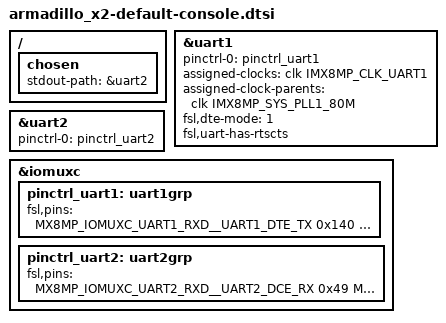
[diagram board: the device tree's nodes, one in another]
/*
 * Copyright (C) 2021 Atmark Techno, Inc. All Rights Reserved.
 *
 * SPDX-License-Identifier: (GPL-2.0 OR MIT)
 */

/ {
	chosen {
		stdout-path = &uart2;
	};
};

&uart1 {
	// M2 slot (bluetooth)
	pinctrl-names = "default";
	pinctrl-0 = <&pinctrl_uart1>;
	assigned-clocks = <&clk IMX8MP_CLK_UART1>;
	assigned-clock-parents = <&clk IMX8MP_SYS_PLL1_80M>;
	status = "okay";
	fsl,dte-mode = <1>;
	fsl,uart-has-rtscts;
};

&uart2 {
	pinctrl-names = "default";
	pinctrl-0 = <&pinctrl_uart2>;
	status = "okay";
};

&iomuxc {
	pinctrl_uart1: uart1grp {
		fsl,pins = <
			MX8MP_IOMUXC_UART1_RXD__UART1_DTE_TX	0x140
			MX8MP_IOMUXC_UART1_TXD__UART1_DTE_RX	0x140
			MX8MP_IOMUXC_UART3_RXD__UART1_DTE_RTS	0x140
			MX8MP_IOMUXC_UART3_TXD__UART1_DTE_CTS	0x140
		>;
	};

	pinctrl_uart2: uart2grp {
		fsl,pins = <
			MX8MP_IOMUXC_UART2_RXD__UART2_DCE_RX	0x49
			MX8MP_IOMUXC_UART2_TXD__UART2_DCE_TX	0x49
		>;
	};
};
